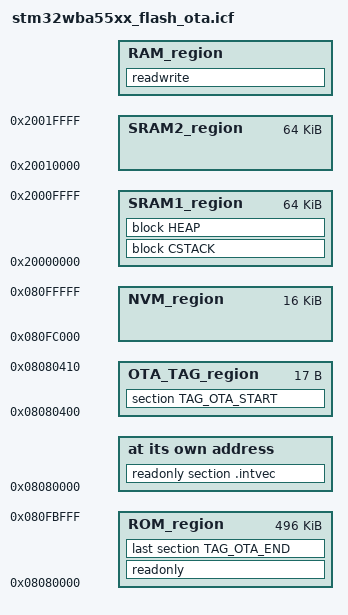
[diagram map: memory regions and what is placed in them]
/*###ICF### Section handled by ICF editor, don't touch! ****/
/*-Editor annotation file-*/
/* IcfEditorFile="$TOOLKIT_DIR$\config\ide\IcfEditor\cortex_v1_0.xml" */
/*-Specials-*/
define symbol __ICFEDIT_intvec_start__ = 0x08080000;
/*-Memory Regions-*/
define symbol __ICFEDIT_region_NVM_size__ = 0x4000;
define symbol __ICFEDIT_region_NVM_end__ = 0x080FFFFF;
define symbol __ICFEDIT_region_NVM_start__ = __ICFEDIT_region_NVM_end__ - __ICFEDIT_region_NVM_size__ + 0x1;
define symbol __ICFEDIT_region_ROM_end__   = __ICFEDIT_region_NVM_start__ - 0x1;
define symbol __ICFEDIT_region_ROM_start__ = 0x08080000;
define symbol __region_SRAM1_start__  = 0x20000000;
define symbol __region_SRAM1_end__    = 0x2000FFFF;
define symbol __region_SRAM2_start__  = 0x20010000;
define symbol __region_SRAM2_end__    = 0x2001FFFF;

/*-Sizes-*/
define symbol __ICFEDIT_size_cstack__ = 0x1000;
define symbol __ICFEDIT_size_heap__   = 0x0400;
/**** End of ICF editor section. ###ICF###*/

define memory mem with size = 4G;
define region NVM_region      = mem:[from __ICFEDIT_region_NVM_start__   to __ICFEDIT_region_NVM_end__];
define region ROM_region      = mem:[from __ICFEDIT_region_ROM_start__   to __ICFEDIT_region_ROM_end__];
define region SRAM1_region    = mem:[from __region_SRAM1_start__   to __region_SRAM1_end__];
define region SRAM2_region    = mem:[from __region_SRAM2_start__   to __region_SRAM2_end__];
define region RAM_region      = SRAM1_region | SRAM2_region ;
define region OTA_TAG_region  = mem:[from (__ICFEDIT_region_ROM_start__ + 0x400)   to (__ICFEDIT_region_ROM_start__ + 0x400 + 0x10)];

define block CSTACK    with alignment = 8, size = __ICFEDIT_size_cstack__   { };
define block HEAP      with alignment = 8, size = __ICFEDIT_size_heap__     { };

initialize by copy { readwrite };
do not initialize  { section .noinit };

place at address mem:__ICFEDIT_intvec_start__ { readonly section .intvec };

keep { section TAG_OTA_START };
keep { section TAG_OTA_END };
place in OTA_TAG_region     { section TAG_OTA_START };
place in ROM_region         { readonly, last section TAG_OTA_END };
place in NVM_region         { };
place in SRAM1_region       { block CSTACK, block HEAP };
place in SRAM2_region       { };
place in RAM_region         { readwrite };
